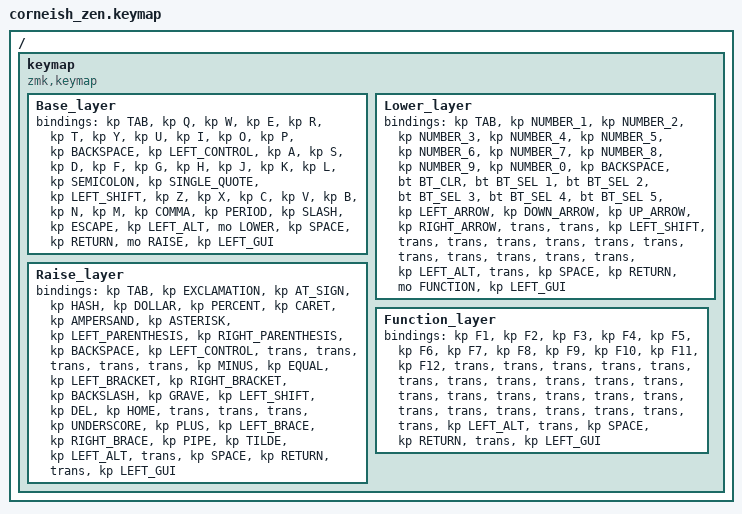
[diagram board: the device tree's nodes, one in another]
#include <behaviors.dtsi>
#include <dt-bindings/zmk/keys.h>
#include <dt-bindings/zmk/bt.h>

#define BASE 0
#define LOWER 1
#define RAISE 2
#define FUNCTION 3

/ {
  keymap {
    compatible = "zmk,keymap";

    Base_layer {
      bindings = <
        &kp TAB &kp Q &kp W &kp E &kp R &kp T &kp Y &kp U &kp I &kp O &kp P &kp BACKSPACE &kp LEFT_CONTROL &kp A &kp S &kp D &kp F &kp G &kp H &kp J &kp K &kp L &kp SEMICOLON &kp SINGLE_QUOTE &kp LEFT_SHIFT &kp Z &kp X &kp C &kp V &kp B &kp N &kp M &kp COMMA &kp PERIOD &kp SLASH &kp ESCAPE &kp LEFT_ALT &mo LOWER &kp SPACE &kp RETURN &mo RAISE &kp LEFT_GUI 
      >;
    };

    Lower_layer {
      bindings = <
        &kp TAB &kp NUMBER_1 &kp NUMBER_2 &kp NUMBER_3 &kp NUMBER_4 &kp NUMBER_5 &kp NUMBER_6 &kp NUMBER_7 &kp NUMBER_8 &kp NUMBER_9 &kp NUMBER_0 &kp BACKSPACE &bt BT_CLR &bt BT_SEL 1 &bt BT_SEL 2 &bt BT_SEL 3 &bt BT_SEL 4 &bt BT_SEL 5 &kp LEFT_ARROW &kp DOWN_ARROW &kp UP_ARROW &kp RIGHT_ARROW &trans &trans &kp LEFT_SHIFT &trans &trans &trans &trans &trans &trans &trans &trans &trans &trans &trans &kp LEFT_ALT &trans &kp SPACE &kp RETURN &mo FUNCTION &kp LEFT_GUI 
      >;
    };

    Raise_layer {
      bindings = <
        &kp TAB &kp EXCLAMATION &kp AT_SIGN &kp HASH &kp DOLLAR &kp PERCENT &kp CARET &kp AMPERSAND &kp ASTERISK &kp LEFT_PARENTHESIS &kp RIGHT_PARENTHESIS &kp BACKSPACE &kp LEFT_CONTROL &trans &trans &trans &trans &trans &kp MINUS &kp EQUAL &kp LEFT_BRACKET &kp RIGHT_BRACKET &kp BACKSLASH &kp GRAVE &kp LEFT_SHIFT &kp DEL &kp HOME &trans &trans &trans &kp UNDERSCORE &kp PLUS &kp LEFT_BRACE &kp RIGHT_BRACE &kp PIPE &kp TILDE &kp LEFT_ALT &trans &kp SPACE &kp RETURN &trans &kp LEFT_GUI 
      >;
    };

    Function_layer {
      bindings = <
        &kp F1 &kp F2 &kp F3 &kp F4 &kp F5 &kp F6 &kp F7 &kp F8 &kp F9 &kp F10 &kp F11 &kp F12 &trans &trans &trans &trans &trans &trans &trans &trans &trans &trans &trans &trans &trans &trans &trans &trans &trans &trans &trans &trans &trans &trans &trans &trans &kp LEFT_ALT &trans &kp SPACE &kp RETURN &trans &kp LEFT_GUI 
      >;
    };

  };
};
